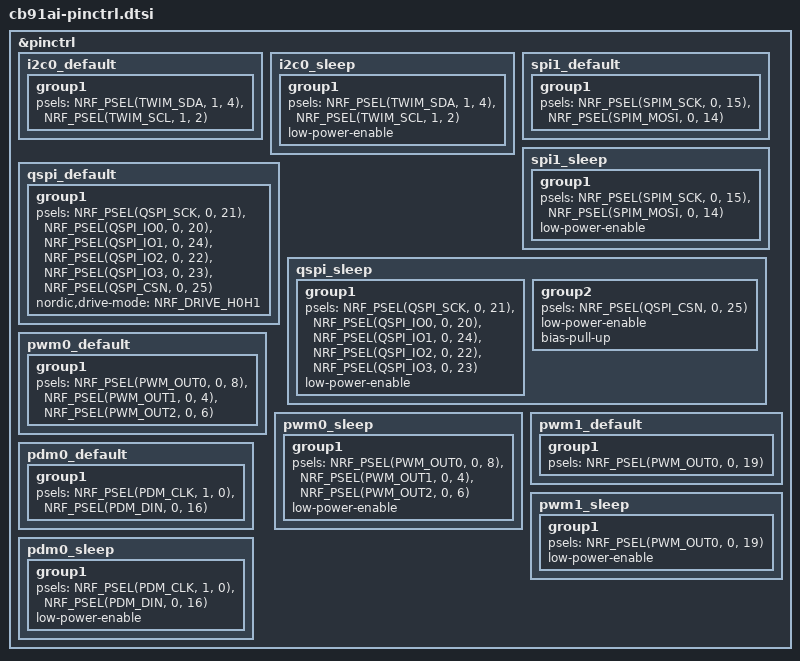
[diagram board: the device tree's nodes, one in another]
/*
 * Copyright (c) 2026 COBALT Technologies
 * SPDX-License-Identifier: Apache-2.0
 *
 * Pin assignment of the COBALT CB-91AI.
 */

&pinctrl {
	/* BMA400 accelerometer, external 10k pull-ups on the board */
	i2c0_default: i2c0_default {
		group1 {
			psels = <NRF_PSEL(TWIM_SDA, 1, 4)>,
				<NRF_PSEL(TWIM_SCL, 1, 2)>;
		};
	};

	i2c0_sleep: i2c0_sleep {
		group1 {
			psels = <NRF_PSEL(TWIM_SDA, 1, 4)>,
				<NRF_PSEL(TWIM_SCL, 1, 2)>;
			low-power-enable;
		};
	};

	/* BU97930 LCD driver: write-only 3-wire SPI, no MISO */
	spi1_default: spi1_default {
		group1 {
			psels = <NRF_PSEL(SPIM_SCK, 0, 15)>,
				<NRF_PSEL(SPIM_MOSI, 0, 14)>;
		};
	};

	spi1_sleep: spi1_sleep {
		group1 {
			psels = <NRF_PSEL(SPIM_SCK, 0, 15)>,
				<NRF_PSEL(SPIM_MOSI, 0, 14)>;
			low-power-enable;
		};
	};

	/* ZD25WQ80C QSPI flash */
	qspi_default: qspi_default {
		group1 {
			psels = <NRF_PSEL(QSPI_SCK, 0, 21)>,
				<NRF_PSEL(QSPI_IO0, 0, 20)>,
				<NRF_PSEL(QSPI_IO1, 0, 24)>,
				<NRF_PSEL(QSPI_IO2, 0, 22)>,
				<NRF_PSEL(QSPI_IO3, 0, 23)>,
				<NRF_PSEL(QSPI_CSN, 0, 25)>;
			nordic,drive-mode = <NRF_DRIVE_H0H1>;
		};
	};

	qspi_sleep: qspi_sleep {
		group1 {
			psels = <NRF_PSEL(QSPI_SCK, 0, 21)>,
				<NRF_PSEL(QSPI_IO0, 0, 20)>,
				<NRF_PSEL(QSPI_IO1, 0, 24)>,
				<NRF_PSEL(QSPI_IO2, 0, 22)>,
				<NRF_PSEL(QSPI_IO3, 0, 23)>;
			low-power-enable;
		};
		group2 {
			psels = <NRF_PSEL(QSPI_CSN, 0, 25)>;
			low-power-enable;
			bias-pull-up;
		};
	};

	/* RGB LED, common anode on the 3V rail: outputs are active low */
	pwm0_default: pwm0_default {
		group1 {
			psels = <NRF_PSEL(PWM_OUT0, 0, 8)>,
				<NRF_PSEL(PWM_OUT1, 0, 4)>,
				<NRF_PSEL(PWM_OUT2, 0, 6)>;
		};
	};

	pwm0_sleep: pwm0_sleep {
		group1 {
			psels = <NRF_PSEL(PWM_OUT0, 0, 8)>,
				<NRF_PSEL(PWM_OUT1, 0, 4)>,
				<NRF_PSEL(PWM_OUT2, 0, 6)>;
			low-power-enable;
		};
	};

	/* Buzzer through Q2 (N-MOS), active high */
	pwm1_default: pwm1_default {
		group1 {
			psels = <NRF_PSEL(PWM_OUT0, 0, 19)>;
		};
	};

	pwm1_sleep: pwm1_sleep {
		group1 {
			psels = <NRF_PSEL(PWM_OUT0, 0, 19)>;
			low-power-enable;
		};
	};

	/* PDM microphone */
	pdm0_default: pdm0_default {
		group1 {
			psels = <NRF_PSEL(PDM_CLK, 1, 0)>,
				<NRF_PSEL(PDM_DIN, 0, 16)>;
		};
	};

	pdm0_sleep: pdm0_sleep {
		group1 {
			psels = <NRF_PSEL(PDM_CLK, 1, 0)>,
				<NRF_PSEL(PDM_DIN, 0, 16)>;
			low-power-enable;
		};
	};
};
